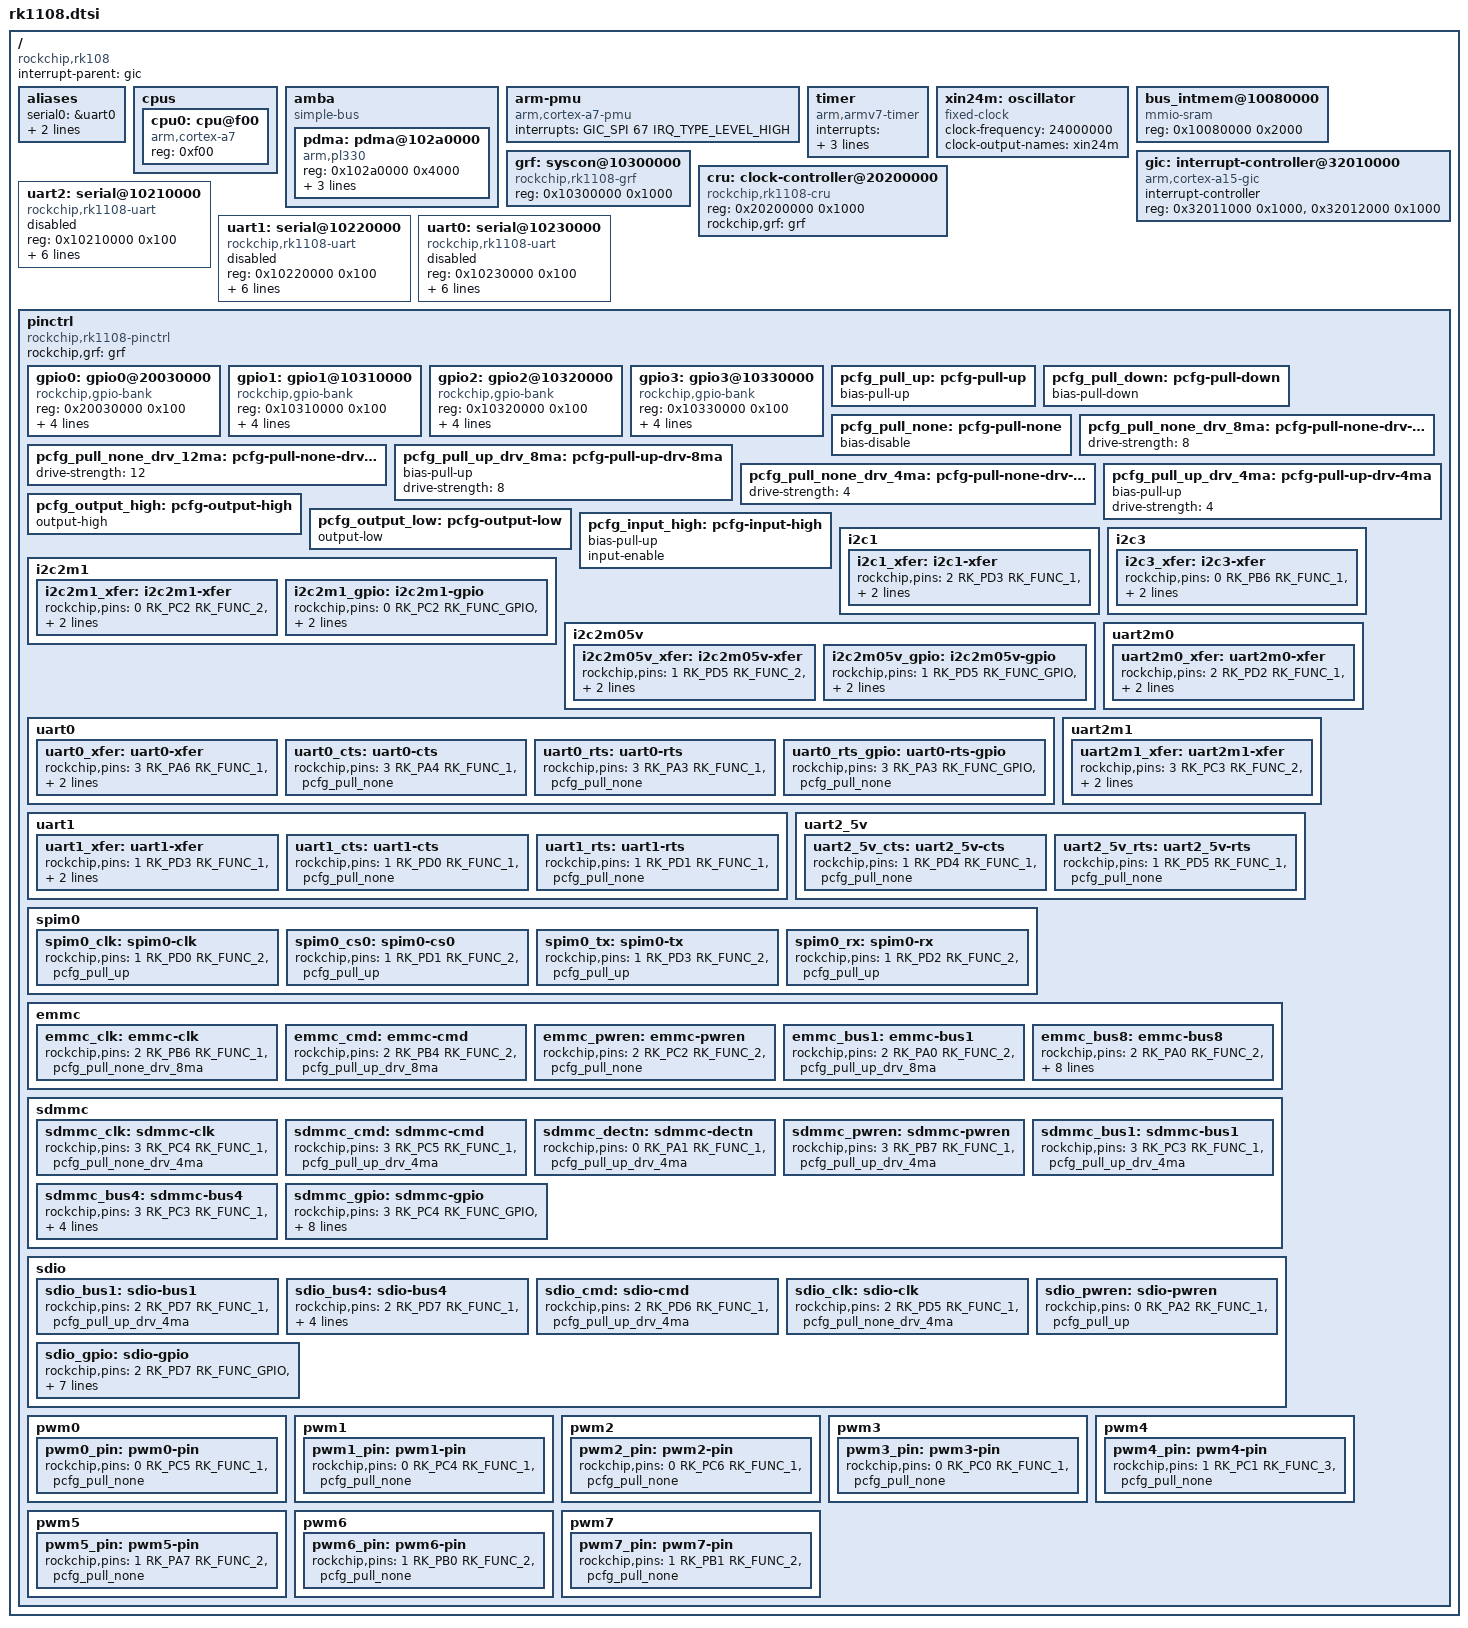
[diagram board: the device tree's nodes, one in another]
/*
 * This file is dual-licensed: you can use it either under the terms
 * of the GPL or the X11 license, at your option. Note that this dual
 * licensing only applies to this file, and not this project as a
 * whole.
 *
 *  a) This file is free software; you can redistribute it and/or
 *     modify it under the terms of the GNU General Public License as
 *     published by the Free Software Foundation; either version 2 of the
 *     License, or (at your option) any later version.
 *
 *     This file is distributed in the hope that it will be useful,
 *     but WITHOUT ANY WARRANTY; without even the implied warranty of
 *     MERCHANTABILITY or FITNESS FOR A PARTICULAR PURPOSE.  See the
 *     GNU General Public License for more details.
 *
 * Or, alternatively,
 *
 *  b) Permission is hereby granted, free of charge, to any person
 *     obtaining a copy of this software and associated documentation
 *     files (the "Software"), to deal in the Software without
 *     restriction, including without limitation the rights to use,
 *     copy, modify, merge, publish, distribute, sublicense, and/or
 *     sell copies of the Software, and to permit persons to whom the
 *     Software is furnished to do so, subject to the following
 *     conditions:
 *
 *     The above copyright notice and this permission notice shall be
 *     included in all copies or substantial portions of the Software.
 *
 *     THE SOFTWARE IS PROVIDED "AS IS", WITHOUT WARRANTY OF ANY KIND,
 *     EXPRESS OR IMPLIED, INCLUDING BUT NOT LIMITED TO THE WARRANTIES
 *     OF MERCHANTABILITY, FITNESS FOR A PARTICULAR PURPOSE AND
 *     NONINFRINGEMENT. IN NO EVENT SHALL THE AUTHORS OR COPYRIGHT
 *     HOLDERS BE LIABLE FOR ANY CLAIM, DAMAGES OR OTHER LIABILITY,
 *     WHETHER IN AN ACTION OF CONTRACT, TORT OR OTHERWISE, ARISING
 *     FROM, OUT OF OR IN CONNECTION WITH THE SOFTWARE OR THE USE OR
 *     OTHER DEALINGS IN THE SOFTWARE.
 */

#include <dt-bindings/gpio/gpio.h>
#include <dt-bindings/interrupt-controller/irq.h>
#include <dt-bindings/interrupt-controller/arm-gic.h>
#include <dt-bindings/clock/rk1108-cru.h>
#include <dt-bindings/pinctrl/rockchip.h>
/ {
	#address-cells = <1>;
	#size-cells = <1>;

	compatible = "rockchip,rk108";

	interrupt-parent = <&gic>;

	aliases {
                serial0 = &uart0;
                serial1 = &uart1;
                serial2 = &uart2;
	};

	cpus {
		#address-cells = <1>;
		#size-cells = <0>;

		cpu0: cpu@f00 {
			device_type = "cpu";
			compatible = "arm,cortex-a7";
			reg = <0xf00>;
		};

	};

	amba {
		compatible = "simple-bus";
		#address-cells = <1>;
		#size-cells = <1>;
		ranges;

		pdma: pdma@102a0000 {
			compatible = "arm,pl330", "arm,primecell";
			reg = <0x102a0000 0x4000>;
			interrupts = <GIC_SPI 0 IRQ_TYPE_LEVEL_HIGH>;
			#dma-cells = <1>;
			arm,pl330-broken-no-flushp;
			clocks = <&cru ACLK_DMAC>;
			clock-names = "apb_pclk";
		};
	};

	arm-pmu {
		compatible = "arm,cortex-a7-pmu";
		interrupts = <GIC_SPI 67 IRQ_TYPE_LEVEL_HIGH>;
	};


	timer {
		compatible = "arm,armv7-timer";
		interrupts = <GIC_PPI 13 (GIC_CPU_MASK_SIMPLE(4) | IRQ_TYPE_LEVEL_HIGH)>,
			     <GIC_PPI 14 (GIC_CPU_MASK_SIMPLE(4) | IRQ_TYPE_LEVEL_HIGH)>;
		clock-frequency = <24000000>;
	};

	xin24m: oscillator {
		compatible = "fixed-clock";
		clock-frequency = <24000000>;
		clock-output-names = "xin24m";
		#clock-cells = <0>;
	};

	bus_intmem@10080000 {
		compatible = "mmio-sram";
		reg = <0x10080000 0x2000>;
		#address-cells = <1>;
		#size-cells = <1>;
		ranges = <0 0x10080000 0x2000>;
	};

	grf: syscon@10300000 {
		compatible = "rockchip,rk1108-grf", "syscon";
		reg = <0x10300000 0x1000>;
	};

	gic: interrupt-controller@32010000 {
		compatible = "arm,cortex-a15-gic";
		interrupt-controller;
		#interrupt-cells = <3>;
		#address-cells = <0>;

		reg = <0x32011000 0x1000>,
		      <0x32012000 0x1000>;

	};
#if 0
	usb_otg: usb@10180000 {
		compatible = "rockchip,rk3036-usb", "rockchip,rk3066-usb",
				"snps,dwc2";
		reg = <0x10180000 0x40000>;
		interrupts = <GIC_SPI 10 IRQ_TYPE_LEVEL_HIGH>;
		clocks = <&cru HCLK_OTG0>;
		clock-names = "otg";
		dr_mode = "otg";
		g-np-tx-fifo-size = <16>;
		g-rx-fifo-size = <275>;
		g-tx-fifo-size = <256 128 128 64 64 32>;
		g-use-dma;
		status = "disabled";
	};

	usb_host: usb@101c0000 {
		compatible = "rockchip,rk3036-usb", "rockchip,rk3066-usb",
				"snps,dwc2";
		reg = <0x101c0000 0x40000>;
		interrupts = <GIC_SPI 11 IRQ_TYPE_LEVEL_HIGH>;
		clocks = <&cru HCLK_OTG1>;
		clock-names = "otg";
		dr_mode = "host";
		status = "disabled";
	};


	sdmmc: dwmmc@10214000 {
		compatible = "rockchip,rk3036-dw-mshc", "rockchip,rk3288-dw-mshc";
		reg = <0x10214000 0x4000>;
		clock-frequency = <37500000>;
		clock-freq-min-max = <400000 37500000>;
		clocks = <&cru HCLK_SDMMC>, <&cru SCLK_SDMMC>;
		clock-names = "biu", "ciu";
		fifo-depth = <0x100>;
		interrupts = <GIC_SPI 14 IRQ_TYPE_LEVEL_HIGH>;
		status = "disabled";
	};

	sdio: dwmmc@10218000 {
		compatible = "rockchip,rk3036-dw-mshc", "rockchip,rk3288-dw-mshc";
		reg = <0x10218000 0x4000>;
		clock-freq-min-max = <400000 37500000>;
		clocks = <&cru HCLK_SDIO>, <&cru SCLK_SDIO>,
			 <&cru SCLK_SDIO_DRV>, <&cru SCLK_SDIO_SAMPLE>;
		clock-names = "biu", "ciu", "ciu_drv", "ciu_sample";
		fifo-depth = <0x100>;
		interrupts = <GIC_SPI 15 IRQ_TYPE_LEVEL_HIGH>;
		status = "disabled";
	};

	emmc: dwmmc@1021c000 {
		compatible = "rockchip,rk3036-dw-mshc", "rockchip,rk3288-dw-mshc";
		reg = <0x1021c000 0x4000>;
		interrupts = <GIC_SPI 16 IRQ_TYPE_LEVEL_HIGH>;
		bus-width = <8>;
		cap-mmc-highspeed;
		clock-frequency = <37500000>;
		clock-freq-min-max = <400000 37500000>;
		clocks = <&cru HCLK_EMMC>, <&cru SCLK_EMMC>,
			 <&cru SCLK_EMMC_DRV>, <&cru SCLK_EMMC_SAMPLE>;
		clock-names = "biu", "ciu", "ciu_drv", "ciu_sample";
		default-sample-phase = <158>;
		disable-wp;
		dmas = <&pdma 12>;
		dma-names = "rx-tx";
		fifo-depth = <0x100>;
		mmc-ddr-1_8v;
		non-removable;
		num-slots = <1>;
		pinctrl-names = "default";
		pinctrl-0 = <&emmc_clk &emmc_cmd &emmc_bus8>;
		status = "disabled";
	};

#endif

	cru: clock-controller@20200000 {
		compatible = "rockchip,rk1108-cru";
		reg = <0x20200000 0x1000>;
		rockchip,grf = <&grf>;
		#clock-cells = <1>;
		#reset-cells = <1>;
	};


/*	acodec: acodec-ana@20030000 {
		compatible = "rk3036-codec";
		reg = <0x20030000 0x4000>;
		rockchip,grf = <&grf>;
		clock-names = "acodec_pclk";
		clocks = <&cru PCLK_ACODEC>;
		status = "disabled";
	};

	hdmi: hdmi@20034000 {
		compatible = "rockchip,rk3036-inno-hdmi";
		reg = <0x20034000 0x4000>;
		interrupts = <GIC_SPI 45 IRQ_TYPE_LEVEL_HIGH>;
		clocks = <&cru  PCLK_HDMI>;
		clock-names = "pclk";
		rockchip,grf = <&grf>;
		pinctrl-names = "default";
		pinctrl-0 = <&hdmi_ctl>;
		status = "disabled";

		hdmi_in: port {
			#address-cells = <1>;
			#size-cells = <0>;
			hdmi_in_vop: endpoint@0 {
				reg = <0>;
				remote-endpoint = <&vop_out_hdmi>;
			};
		};
	};

	timer: timer@20044000 {
		compatible = "rockchip,rk3036-timer", "rockchip,rk3288-timer";
		reg = <0x20044000 0x20>;
		interrupts = <GIC_SPI 28 IRQ_TYPE_LEVEL_HIGH>;
		clocks = <&xin24m>, <&cru PCLK_TIMER>;
		clock-names = "timer", "pclk";
	};

	pwm0: pwm@20050000 {
		compatible = "rockchip,rk3036-pwm", "rockchip,rk2928-pwm";
		reg = <0x20050000 0x10>;
		#pwm-cells = <3>;
		clocks = <&cru PCLK_PWM>;
		clock-names = "pwm";
		pinctrl-names = "default";
		pinctrl-0 = <&pwm0_pin>;
		status = "disabled";
	};

	pwm1: pwm@20050010 {
		compatible = "rockchip,rk3036-pwm", "rockchip,rk2928-pwm";
		reg = <0x20050010 0x10>;
		#pwm-cells = <3>;
		clocks = <&cru PCLK_PWM>;
		clock-names = "pwm";
		pinctrl-names = "default";
		pinctrl-0 = <&pwm1_pin>;
		status = "disabled";
	};

	pwm2: pwm@20050020 {
		compatible = "rockchip,rk3036-pwm", "rockchip,rk2928-pwm";
		reg = <0x20050020 0x10>;
		#pwm-cells = <3>;
		clocks = <&cru PCLK_PWM>;
		clock-names = "pwm";
		pinctrl-names = "default";
		pinctrl-0 = <&pwm2_pin>;
		status = "disabled";
	};

	pwm3: pwm@20050030 {
		compatible = "rockchip,rk3036-pwm", "rockchip,rk2928-pwm";
		reg = <0x20050030 0x10>;
		#pwm-cells = <2>;
		clocks = <&cru PCLK_PWM>;
		clock-names = "pwm";
		pinctrl-names = "default";
		pinctrl-0 = <&pwm3_pin>;
		status = "disabled";
	};

	i2c1: i2c@20056000 {
		compatible = "rockchip,rk3036-i2c", "rockchip,rk3288-i2c";
		reg = <0x20056000 0x1000>;
		interrupts = <GIC_SPI 25 IRQ_TYPE_LEVEL_HIGH>;
		#address-cells = <1>;
		#size-cells = <0>;
		clock-names = "i2c";
		clocks = <&cru PCLK_I2C1>;
		pinctrl-names = "default";
		pinctrl-0 = <&i2c1_xfer>;
		status = "disabled";
	};

	i2c2: i2c@2005a000 {
		compatible = "rockchip,rk3036-i2c", "rockchip,rk3288-i2c";
		reg = <0x2005a000 0x1000>;
		interrupts = <GIC_SPI 26 IRQ_TYPE_LEVEL_HIGH>;
		#address-cells = <1>;
		#size-cells = <0>;
		clock-names = "i2c";
		clocks = <&cru PCLK_I2C2>;
		pinctrl-names = "default";
		pinctrl-0 = <&i2c2_xfer>;
		status = "disabled";
	};*/

	uart2: serial@10210000 {
		compatible = "rockchip,rk1108-uart", "snps,dw-apb-uart";
		reg = <0x10210000 0x100>;
		interrupts = <GIC_SPI 46 IRQ_TYPE_LEVEL_HIGH>;
		reg-shift = <2>;
		reg-io-width = <4>;
		clock-frequency = <24000000>;
		clocks = <&cru SCLK_UART2>, <&cru PCLK_UART2>;
		clock-names = "baudclk", "apb_pclk";
		pinctrl-names = "default";
		pinctrl-0 = <&uart2m0_xfer>;
		status = "disabled";
	};

	uart1: serial@10220000 {
		compatible = "rockchip,rk1108-uart", "snps,dw-apb-uart";
		reg = <0x10220000 0x100>;
		interrupts = <GIC_SPI 45 IRQ_TYPE_LEVEL_HIGH>;
		reg-shift = <2>;
		reg-io-width = <4>;
		clock-frequency = <24000000>;
		clocks = <&cru SCLK_UART1>, <&cru PCLK_UART1>;
		clock-names = "baudclk", "apb_pclk";
		pinctrl-names = "default";
		pinctrl-0 = <&uart1_xfer>;
		status = "disabled";
	};

	uart0: serial@10230000 {
		compatible = "rockchip,rk1108-uart", "snps,dw-apb-uart";
		reg = <0x10230000 0x100>;
		interrupts = <GIC_SPI 44 IRQ_TYPE_LEVEL_HIGH>;
		reg-shift = <2>;
		reg-io-width = <4>;
		clock-frequency = <24000000>;
		clocks = <&cru SCLK_UART0>, <&cru PCLK_UART0>;
		clock-names = "baudclk", "apb_pclk";
		pinctrl-names = "default";
		pinctrl-0 = <&uart0_xfer &uart0_cts &uart0_rts>;
		status = "disabled";
	};

	/*i2c0: i2c@20072000 {
		compatible = "rockchip,rk3036-i2c", "rockchip,rk3288-i2c";
		reg = <0x20072000 0x1000>;
		interrupts = <GIC_SPI 24 IRQ_TYPE_LEVEL_HIGH>;
		#address-cells = <1>;
		#size-cells = <0>;
		clock-names = "i2c";
		clocks = <&cru PCLK_I2C0>;
		pinctrl-names = "default";
		pinctrl-0 = <&i2c0_xfer>;
		status = "disabled";
	};

	spi: spi@20074000 {
		compatible = "rockchip,rockchip-spi";
		reg = <0x20074000 0x1000>;
		interrupts = <GIC_SPI 23 IRQ_TYPE_LEVEL_HIGH>;
		clocks =<&cru PCLK_SPI>, <&cru SCLK_SPI>;
		clock-names = "apb-pclk","spi_pclk";
		dmas = <&pdma 8>, <&pdma 9>;
		dma-names = "tx", "rx";
		pinctrl-names = "default";
		pinctrl-0 = <&spi_txd &spi_rxd &spi_clk &spi_cs0>;
		#address-cells = <1>;
		#size-cells = <0>;
		status = "disabled";
	};*/

	pinctrl: pinctrl {
		compatible = "rockchip,rk1108-pinctrl";
		rockchip,grf = <&grf>;
		#address-cells = <1>;
		#size-cells = <1>;
		ranges;

		gpio0: gpio0@20030000 {
			compatible = "rockchip,gpio-bank";
			reg = <0x20030000 0x100>;
			interrupts = <GIC_SPI 40 IRQ_TYPE_LEVEL_HIGH>;
			clocks = <&xin24m>;

			gpio-controller;
			#gpio-cells = <2>;

			interrupt-controller;
			#interrupt-cells = <2>;
		};

		gpio1: gpio1@10310000 {
			compatible = "rockchip,gpio-bank";
			reg = <0x10310000 0x100>;
			interrupts = <GIC_SPI 41 IRQ_TYPE_LEVEL_HIGH>;
			clocks = <&xin24m>;

			gpio-controller;
			#gpio-cells = <2>;

			interrupt-controller;
			#interrupt-cells = <2>;
		};

		gpio2: gpio2@10320000 {
			compatible = "rockchip,gpio-bank";
			reg = <0x10320000 0x100>;
			interrupts = <GIC_SPI 42 IRQ_TYPE_LEVEL_HIGH>;
			clocks = <&xin24m>;

			gpio-controller;
			#gpio-cells = <2>;

			interrupt-controller;
			#interrupt-cells = <2>;
		};

		gpio3: gpio3@10330000 {
			compatible = "rockchip,gpio-bank";
			reg = <0x10330000 0x100>;
			interrupts = <GIC_SPI 43 IRQ_TYPE_LEVEL_HIGH>;
			clocks = <&xin24m>;

			gpio-controller;
			#gpio-cells = <2>;

			interrupt-controller;
			#interrupt-cells = <2>;
		};

		pcfg_pull_up: pcfg-pull-up {
			bias-pull-up;
		};

		pcfg_pull_down: pcfg-pull-down {
			bias-pull-down;
		};

		pcfg_pull_none: pcfg-pull-none {
			bias-disable;
		};

		pcfg_pull_none_drv_8ma: pcfg-pull-none-drv-8ma {
			drive-strength = <8>;
		};

		pcfg_pull_none_drv_12ma: pcfg-pull-none-drv-12ma {
			drive-strength = <12>;
		};

		pcfg_pull_up_drv_8ma: pcfg-pull-up-drv-8ma {
			bias-pull-up;
			drive-strength = <8>;
		};

		pcfg_pull_none_drv_4ma: pcfg-pull-none-drv-4ma {
			drive-strength = <4>;
		};

		pcfg_pull_up_drv_4ma: pcfg-pull-up-drv-4ma {
			bias-pull-up;
			drive-strength = <4>;
		};

		pcfg_output_high: pcfg-output-high {
			output-high;
		};

		pcfg_output_low: pcfg-output-low {
			output-low;
		};

		pcfg_input_high: pcfg-input-high {
			bias-pull-up;
			input-enable;
		};

		i2c1 {
			i2c1_xfer: i2c1-xfer {
				rockchip,pins = <2 RK_PD3 RK_FUNC_1 &pcfg_pull_up>,
						<2 RK_PD4 RK_FUNC_1 &pcfg_pull_up>;
			};
		};

		i2c2m1 {
			i2c2m1_xfer: i2c2m1-xfer {
				rockchip,pins = <0 RK_PC2 RK_FUNC_2 &pcfg_pull_none>,
						<0 RK_PC6 RK_FUNC_3 &pcfg_pull_none>;
			};

			i2c2m1_gpio: i2c2m1-gpio {
				rockchip,pins = <0 RK_PC2 RK_FUNC_GPIO &pcfg_pull_none>,
						<0 RK_PC6 RK_FUNC_GPIO &pcfg_pull_none>;
			};
		};

		i2c2m05v {
			i2c2m05v_xfer: i2c2m05v-xfer {
				rockchip,pins = <1 RK_PD5 RK_FUNC_2 &pcfg_pull_none>,
						<1 RK_PD4 RK_FUNC_2 &pcfg_pull_none>;
			};

			i2c2m05v_gpio: i2c2m05v-gpio {
				rockchip,pins = <1 RK_PD5 RK_FUNC_GPIO &pcfg_pull_none>,
						<1 RK_PD4 RK_FUNC_GPIO &pcfg_pull_none>;
			};
		};

		i2c3 {
			i2c3_xfer: i2c3-xfer {
				rockchip,pins = <0 RK_PB6 RK_FUNC_1 &pcfg_pull_none>,
						<0 RK_PC4 RK_FUNC_2 &pcfg_pull_none>;
			};
		};

		uart0 {
			uart0_xfer: uart0-xfer {
				rockchip,pins = <3 RK_PA6 RK_FUNC_1 &pcfg_pull_up>,
						<3 RK_PA5 RK_FUNC_1 &pcfg_pull_none>;
			};

			uart0_cts: uart0-cts {
				rockchip,pins = <3 RK_PA4 RK_FUNC_1 &pcfg_pull_none>;
			};

			uart0_rts: uart0-rts {
				rockchip,pins = <3 RK_PA3 RK_FUNC_1 &pcfg_pull_none>;
			};

			uart0_rts_gpio: uart0-rts-gpio {
				rockchip,pins = <3 RK_PA3 RK_FUNC_GPIO &pcfg_pull_none>;
			};
		};

		uart1 {
			uart1_xfer: uart1-xfer {
				rockchip,pins = <1 RK_PD3 RK_FUNC_1 &pcfg_pull_up>,
						<1 RK_PD2 RK_FUNC_1 &pcfg_pull_none>;
			};

			uart1_cts: uart1-cts {
				rockchip,pins = <1 RK_PD0 RK_FUNC_1 &pcfg_pull_none>;
			};

			uart1_rts: uart1-rts {
				rockchip,pins = <1 RK_PD1 RK_FUNC_1 &pcfg_pull_none>;
			};
		};

		uart2m0 {
			uart2m0_xfer: uart2m0-xfer {
				rockchip,pins = <2 RK_PD2 RK_FUNC_1 &pcfg_pull_up>,
						<2 RK_PD1 RK_FUNC_1 &pcfg_pull_none>;
			};
		};

		uart2m1 {
			uart2m1_xfer: uart2m1-xfer {
				rockchip,pins = <3 RK_PC3 RK_FUNC_2 &pcfg_pull_up>,
						<3 RK_PC2 RK_FUNC_2 &pcfg_pull_none>;
			};
		};

		uart2_5v {
			uart2_5v_cts: uart2_5v-cts {
				rockchip,pins = <1 RK_PD4 RK_FUNC_1 &pcfg_pull_none>;
			};

			uart2_5v_rts: uart2_5v-rts {
				rockchip,pins = <1 RK_PD5 RK_FUNC_1 &pcfg_pull_none>;
			};
		};

		spim0 {
			spim0_clk: spim0-clk {
				rockchip,pins = <1 RK_PD0 RK_FUNC_2 &pcfg_pull_up>;
			};

			spim0_cs0: spim0-cs0 {
				rockchip,pins = <1 RK_PD1 RK_FUNC_2 &pcfg_pull_up>;
			};

			spim0_tx: spim0-tx {
				rockchip,pins = <1 RK_PD3 RK_FUNC_2 &pcfg_pull_up>;
			};

			spim0_rx: spim0-rx {
				rockchip,pins = <1 RK_PD2 RK_FUNC_2 &pcfg_pull_up>;
			};
		};

		emmc {
                        emmc_clk: emmc-clk {
                                rockchip,pins = <2 RK_PB6 RK_FUNC_1 &pcfg_pull_none_drv_8ma>;
                        };

                        emmc_cmd: emmc-cmd {
                                rockchip,pins = <2 RK_PB4 RK_FUNC_2 &pcfg_pull_up_drv_8ma>;
                        };

                        emmc_pwren: emmc-pwren {
                                rockchip,pins = <2 RK_PC2 RK_FUNC_2 &pcfg_pull_none>;
                        };

                        emmc_bus1: emmc-bus1 {
                                rockchip,pins = <2 RK_PA0 RK_FUNC_2 &pcfg_pull_up_drv_8ma>;
                        };

                        emmc_bus8: emmc-bus8 {
                                rockchip,pins = <2 RK_PA0 RK_FUNC_2 &pcfg_pull_up_drv_8ma>,
                                                <2 RK_PA1 RK_FUNC_2 &pcfg_pull_up_drv_8ma>,
                                                <2 RK_PA2 RK_FUNC_2 &pcfg_pull_up_drv_8ma>,
                                                <2 RK_PA3 RK_FUNC_2 &pcfg_pull_up_drv_8ma>,
                                                <2 RK_PA4 RK_FUNC_2 &pcfg_pull_up_drv_8ma>,
                                                <2 RK_PA5 RK_FUNC_2 &pcfg_pull_up_drv_8ma>,
                                                <2 RK_PA6 RK_FUNC_2 &pcfg_pull_up_drv_8ma>,
                                                <2 RK_PA7 RK_FUNC_2 &pcfg_pull_up_drv_8ma>;
                        };
                };

		sdmmc {
                        sdmmc_clk: sdmmc-clk {
                                rockchip,pins = <3 RK_PC4 RK_FUNC_1 &pcfg_pull_none_drv_4ma>;
                        };

                        sdmmc_cmd: sdmmc-cmd {
                                rockchip,pins = <3 RK_PC5 RK_FUNC_1 &pcfg_pull_up_drv_4ma>;
                        };

                        sdmmc_dectn: sdmmc-dectn {
                                rockchip,pins = <0 RK_PA1 RK_FUNC_1 &pcfg_pull_up_drv_4ma>;
                        };

                        sdmmc_pwren: sdmmc-pwren {
                                rockchip,pins = <3 RK_PB7 RK_FUNC_1 &pcfg_pull_up_drv_4ma>;
                        };

                        sdmmc_bus1: sdmmc-bus1 {
                                rockchip,pins = <3 RK_PC3 RK_FUNC_1 &pcfg_pull_up_drv_4ma>;
                        };

                        sdmmc_bus4: sdmmc-bus4 {
                                rockchip,pins = <3 RK_PC3 RK_FUNC_1 &pcfg_pull_up_drv_4ma>,
                                                <3 RK_PC2 RK_FUNC_1 &pcfg_pull_up_drv_4ma>,
                                                <3 RK_PC1 RK_FUNC_1 &pcfg_pull_up_drv_4ma>,
                                                <3 RK_PC0 RK_FUNC_1 &pcfg_pull_up_drv_4ma>;
                        };

                        sdmmc_gpio: sdmmc-gpio {
                                rockchip,pins = <3 RK_PC4 RK_FUNC_GPIO &pcfg_pull_up_drv_4ma>,
                                                <3 RK_PC5 RK_FUNC_GPIO &pcfg_pull_up_drv_4ma>,
                                                <0 RK_PA1 RK_FUNC_GPIO &pcfg_pull_up_drv_4ma>,
                                                <3 RK_PB7 RK_FUNC_GPIO &pcfg_pull_up_drv_4ma>,
                                                <3 RK_PC3 RK_FUNC_GPIO &pcfg_pull_up_drv_4ma>,
                                                <3 RK_PC2 RK_FUNC_GPIO &pcfg_pull_up_drv_4ma>,
                                                <3 RK_PC1 RK_FUNC_GPIO &pcfg_pull_up_drv_4ma>,
                                                <3 RK_PC0 RK_FUNC_GPIO &pcfg_pull_up_drv_4ma>;
                        };
                };

		sdio {
                        sdio_bus1: sdio-bus1 {
                                rockchip,pins = <2 RK_PD7 RK_FUNC_1 &pcfg_pull_up_drv_4ma>;
                        };

                        sdio_bus4: sdio-bus4 {
                                rockchip,pins = <2 RK_PD7 RK_FUNC_1 &pcfg_pull_up_drv_4ma>,
                                                <3 RK_PA0 RK_FUNC_1 &pcfg_pull_up_drv_4ma>,
                                                <3 RK_PA1 RK_FUNC_1 &pcfg_pull_up_drv_4ma>,
                                                <3 RK_PA2 RK_FUNC_1 &pcfg_pull_up_drv_4ma>;
                        };

                        sdio_cmd: sdio-cmd {
                                rockchip,pins = <2 RK_PD6 RK_FUNC_1 &pcfg_pull_up_drv_4ma>;
                        };

                        sdio_clk: sdio-clk {
                                rockchip,pins = <2 RK_PD5 RK_FUNC_1 &pcfg_pull_none_drv_4ma>;
                        };

                        sdio_pwren: sdio-pwren {
                                rockchip,pins = <0 RK_PA2 RK_FUNC_1 &pcfg_pull_up>;
                        };

                        sdio_gpio: sdio-gpio {
                                rockchip,pins = <2 RK_PD7 RK_FUNC_GPIO &pcfg_pull_up_drv_4ma>,
                                                <3 RK_PA0 RK_FUNC_GPIO &pcfg_pull_up_drv_4ma>,
                                                <3 RK_PA1 RK_FUNC_GPIO &pcfg_pull_up_drv_4ma>,
                                                <3 RK_PA2 RK_FUNC_GPIO &pcfg_pull_up_drv_4ma>,
                                                <2 RK_PD6 RK_FUNC_GPIO &pcfg_pull_up_drv_4ma>,
                                                <2 RK_PD5 RK_FUNC_GPIO &pcfg_pull_up_drv_4ma>,
                                                <0 RK_PA2 RK_FUNC_GPIO &pcfg_pull_up_drv_4ma>;
                        };
                };

		pwm0 {
                        pwm0_pin: pwm0-pin {
                                rockchip,pins = <0 RK_PC5 RK_FUNC_1 &pcfg_pull_none>;
                        };
                };

                pwm1 {
                        pwm1_pin: pwm1-pin {
                                rockchip,pins = <0 RK_PC4 RK_FUNC_1 &pcfg_pull_none>;
                        };
                };

                pwm2 {
                        pwm2_pin: pwm2-pin {
                                rockchip,pins = <0 RK_PC6 RK_FUNC_1 &pcfg_pull_none>;
                        };
                };

                pwm3 {
                        pwm3_pin: pwm3-pin {
                                rockchip,pins = <0 RK_PC0 RK_FUNC_1 &pcfg_pull_none>;
                        };
                };

                pwm4 {
                        pwm4_pin: pwm4-pin {
                                rockchip,pins = <1 RK_PC1 RK_FUNC_3 &pcfg_pull_none>;
                        };
                };

                pwm5 {
                        pwm5_pin: pwm5-pin {
                                rockchip,pins = <1 RK_PA7 RK_FUNC_2 &pcfg_pull_none>;
                        };
                };

                pwm6 {
                        pwm6_pin: pwm6-pin {
                                rockchip,pins = <1 RK_PB0 RK_FUNC_2 &pcfg_pull_none>;
                        };
                };

		pwm7 {
                        pwm7_pin: pwm7-pin {
                                rockchip,pins = <1 RK_PB1 RK_FUNC_2 &pcfg_pull_none>;
                        };
                };

	};
};
